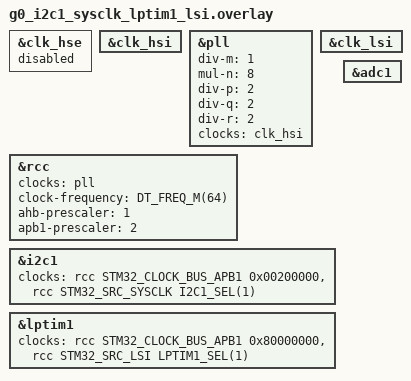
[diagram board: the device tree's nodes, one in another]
/*
 * Copyright (c) 2022 Linaro Limited
 *
 * SPDX-License-Identifier: Apache-2.0
 */

/* Clocks clean up config
 * Aim is to avoid conflict with specific default board configuration
 */

&clk_hse {
	status = "disabled";
	/delete-property/ hse-bypass;
	/delete-property/ clock-frequency;
};

&clk_hsi {
	status = "disabled";
};

&pll {
	/delete-property/ div-m;
	/delete-property/ mul-n;
	/delete-property/ div-p;
	/delete-property/ div-q;
	/delete-property/ div-r;
	/delete-property/ clocks;
	status = "disabled";
};

&rcc {
	/delete-property/ clocks;
	/delete-property/ clock-frequency;
};


/* Core set up
 * Aim of this part is to provide a base working clock config
 */

&clk_hsi {
	status = "okay";
};

&clk_lsi {
	status = "okay";
};

&pll {
	div-m = <1>;
	mul-n = <8>;
	div-p = <2>;
	div-q = <2>;
	div-r = <2>;
	clocks = <&clk_hsi>;
	status = "okay";
};

&rcc {
	clocks = <&pll>;
	clock-frequency = <DT_FREQ_M(64)>;
	ahb-prescaler = <1>;
	apb1-prescaler = <2>;
};

&i2c1 {
	/delete-property/ clocks;
	clocks = <&rcc STM32_CLOCK_BUS_APB1 0x00200000>,
			<&rcc STM32_SRC_SYSCLK I2C1_SEL(1)>;
	status = "okay";
};

&lptim1 {
	clocks = <&rcc STM32_CLOCK_BUS_APB1 0x80000000>,
			<&rcc STM32_SRC_LSI LPTIM1_SEL(1)>;
	status = "okay";
};

&adc1 {
	/* Basic test only. ADC1 domain clock is set by the board DTS : SYSCLK */
	status = "okay";
};
